# STM32WBAxx register map
File version: 0.1
Registers are 32-bit, read-write, reset 0x0 unless marked. A register's access mark holds for its fields unless they carry their own. Offsets are from the block's base; [hi:lo] are bit positions.

## FMAC — Filter Math Accelerator
Base 0x40021400
Same registers: SEC_FMAC 0x50021400
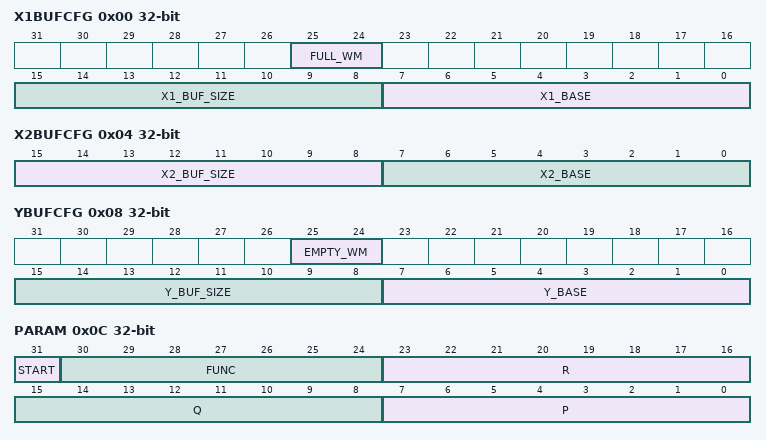
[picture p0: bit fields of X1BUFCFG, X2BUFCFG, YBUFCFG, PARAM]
0x00 X1BUFCFG — FMAC X1 Buffer Configuration register
  [25:24] FULL_WM — Watermark for buffer full flag
  [15:8] X1_BUF_SIZE — Allocated size of X1 buffer in 16-bit words
  [7:0] X1_BASE — Base address of X1 buffer
0x04 X2BUFCFG — FMAC X2 Buffer Configuration register
  [15:8] X2_BUF_SIZE — Size of X2 buffer in 16-bit words
  [7:0] X2_BASE — Base address of X2 buffer
0x08 YBUFCFG — FMAC Y Buffer Configuration register
  [25:24] EMPTY_WM — Watermark for buffer empty flag
  [15:8] Y_BUF_SIZE — Size of Y buffer in 16-bit words
  [7:0] Y_BASE — Base address of Y buffer
0x0C PARAM — FMAC Parameter register
  [31] START — Enable execution
  [30:24] FUNC — Function
  [23:16] R — Input parameter R
  [15:8] Q — Input parameter Q
  [7:0] P — Input parameter P
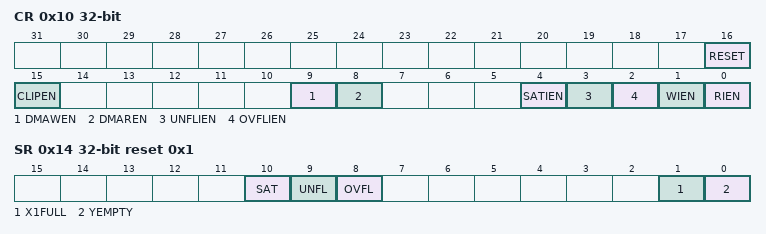
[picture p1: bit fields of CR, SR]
0x10 CR — FMAC Control register
  [16] RESET — Reset FMAC unit
  [15] CLIPEN — Enable clipping
  [9] DMAWEN — Enable DMA write channel requests
  [8] DMAREN — Enable DMA read channel requests
  [4] SATIEN — Enable saturation error interrupts
  [3] UNFLIEN — Enable underflow error interrupts
  [2] OVFLIEN — Enable overflow error interrupts
  [1] WIEN — Enable write interrupt
  [0] RIEN — Enable read interrupt
0x14 SR ro reset 0x1 — FMAC Status register
  [10] SAT — Saturation error flag
  [9] UNFL — Underflow error flag
  [8] OVFL — Overflow error flag
  [1] X1FULL — X1 buffer full flag
  [0] YEMPTY — Y buffer empty flag
0x18 WDATA wo — FMAC Write Data register
  [15:0] WDATA — Write data
0x1C RDATA ro — FMAC Read Data register
  [15:0] RDATA — Read data

## CORDIC — CORDIC Co-processor
Base 0x40021000
Same registers: SEC_CORDIC 0x50021000
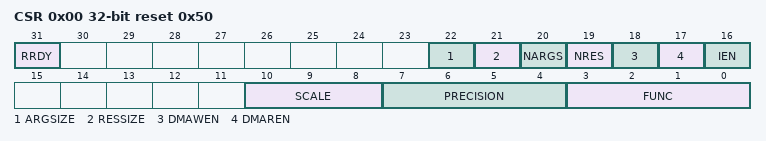
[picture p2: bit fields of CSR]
0x00 CSR access per field reset 0x50 — CORDIC Control Status register
  [31] RRDY ro — Result ready flag
  [22] ARGSIZE rw — Width of input data
  [21] RESSIZE rw — Width of output data
  [20] NARGS rw — Number of arguments expected by the CORDIC_WDATA register
  [19] NRES rw — Number of results in the CORDIC_RDATA register
  [18] DMAWEN rw — Enable DMA write channel
  [17] DMAREN rw — Enable DMA read channel
  [16] IEN rw — Enable interrupt
  [10:8] SCALE rw — Scaling factor
  [7:4] PRECISION rw — Precision required (number of iterations)
  [3:0] FUNC rw — Function
0x04 WDATA wo — FMAC Write Data register
  [31:0] ARG — Function input arguments
0x08 RDATA ro — FMAC Read Data register
  [31:0] RES — Function result

## OPAMP — Operational amplifiers
Base 0x46005000
Same registers: SEC_OPAMP 0x56005000
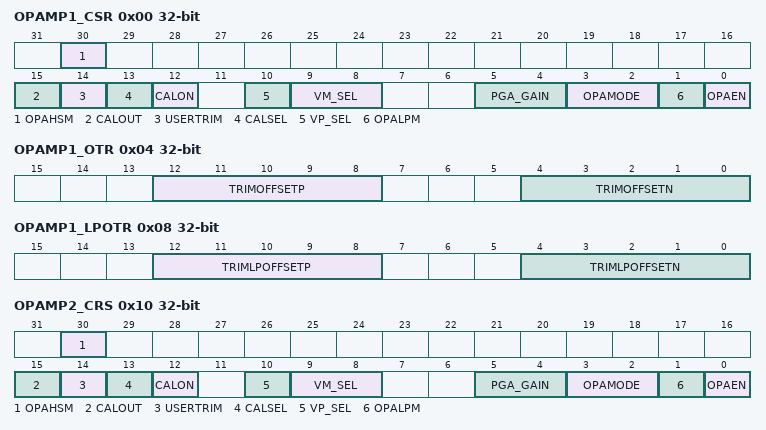
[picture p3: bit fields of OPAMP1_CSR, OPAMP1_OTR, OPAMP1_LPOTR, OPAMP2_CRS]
0x00 OPAMP1_CSR — OPAMP1 control/status register
  [30] OPAHSM
  [15] CALOUT
  [14] USERTRIM
  [13] CALSEL
  [12] CALON
  [10] VP_SEL
  [9:8] VM_SEL
  [5:4] PGA_GAIN — USERTRIM
  [3:2] OPAMODE
  [1] OPALPM
  [0] OPAEN — Operational amplifier Enable
0x04 OPAMP1_OTR — offset trimming register in normal mode
  [12:8] TRIMOFFSETP, [4:0] TRIMOFFSETN
0x08 OPAMP1_LPOTR — offset trimming register in low-power mode
  [12:8] TRIMLPOFFSETP, [4:0] TRIMLPOFFSETN
0x10 OPAMP2_CRS access per field — control/status register
  [30] OPAHSM rw, [15] CALOUT ro, [14] USERTRIM rw, [13] CALSEL rw, [12] CALON rw, [10] VP_SEL rw, [9:8] VM_SEL rw, [5:4] PGA_GAIN rw, [3:2] OPAMODE rw, [1] OPALPM rw, [0] OPAEN rw
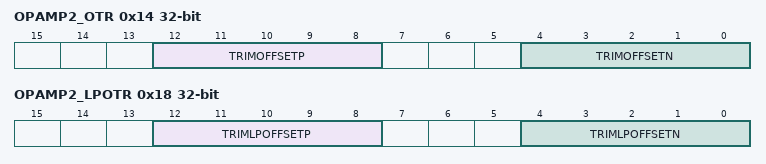
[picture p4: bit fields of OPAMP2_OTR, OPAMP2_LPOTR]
0x14 OPAMP2_OTR — offset trimming register in normal mode
  [12:8] TRIMOFFSETP, [4:0] TRIMOFFSETN
0x18 OPAMP2_LPOTR — offset trimming register in low-power mode
  [12:8] TRIMLPOFFSETP, [4:0] TRIMLPOFFSETN

## DLYBOS1 — The delay block (DLYB) is used to generate an output clock that is dephased from the input clock
Base 0x420CF000
Same registers: DLYBSD1 0x420C8400, DLYBSD2 0x420C8800, DLYBOS2 0x420CF400, SEC_DLYBSD1 0x520C8400, SEC_DLYBSD2 0x520C8800, SEC_DLYBOS1 0x520CF000, SEC_DLYBOS2 0x520CF400
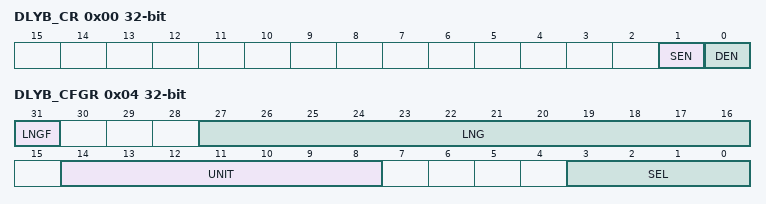
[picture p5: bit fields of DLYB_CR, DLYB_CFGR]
0x00 DLYB_CR — control register
  [1] SEN — OPALPM
  [0] DEN — Operational amplifier Enable
0x04 DLYB_CFGR access per field — configuration register
  [31] LNGF ro, [27:16] LNG ro, [14:8] UNIT rw, [3:0] SEL rw
